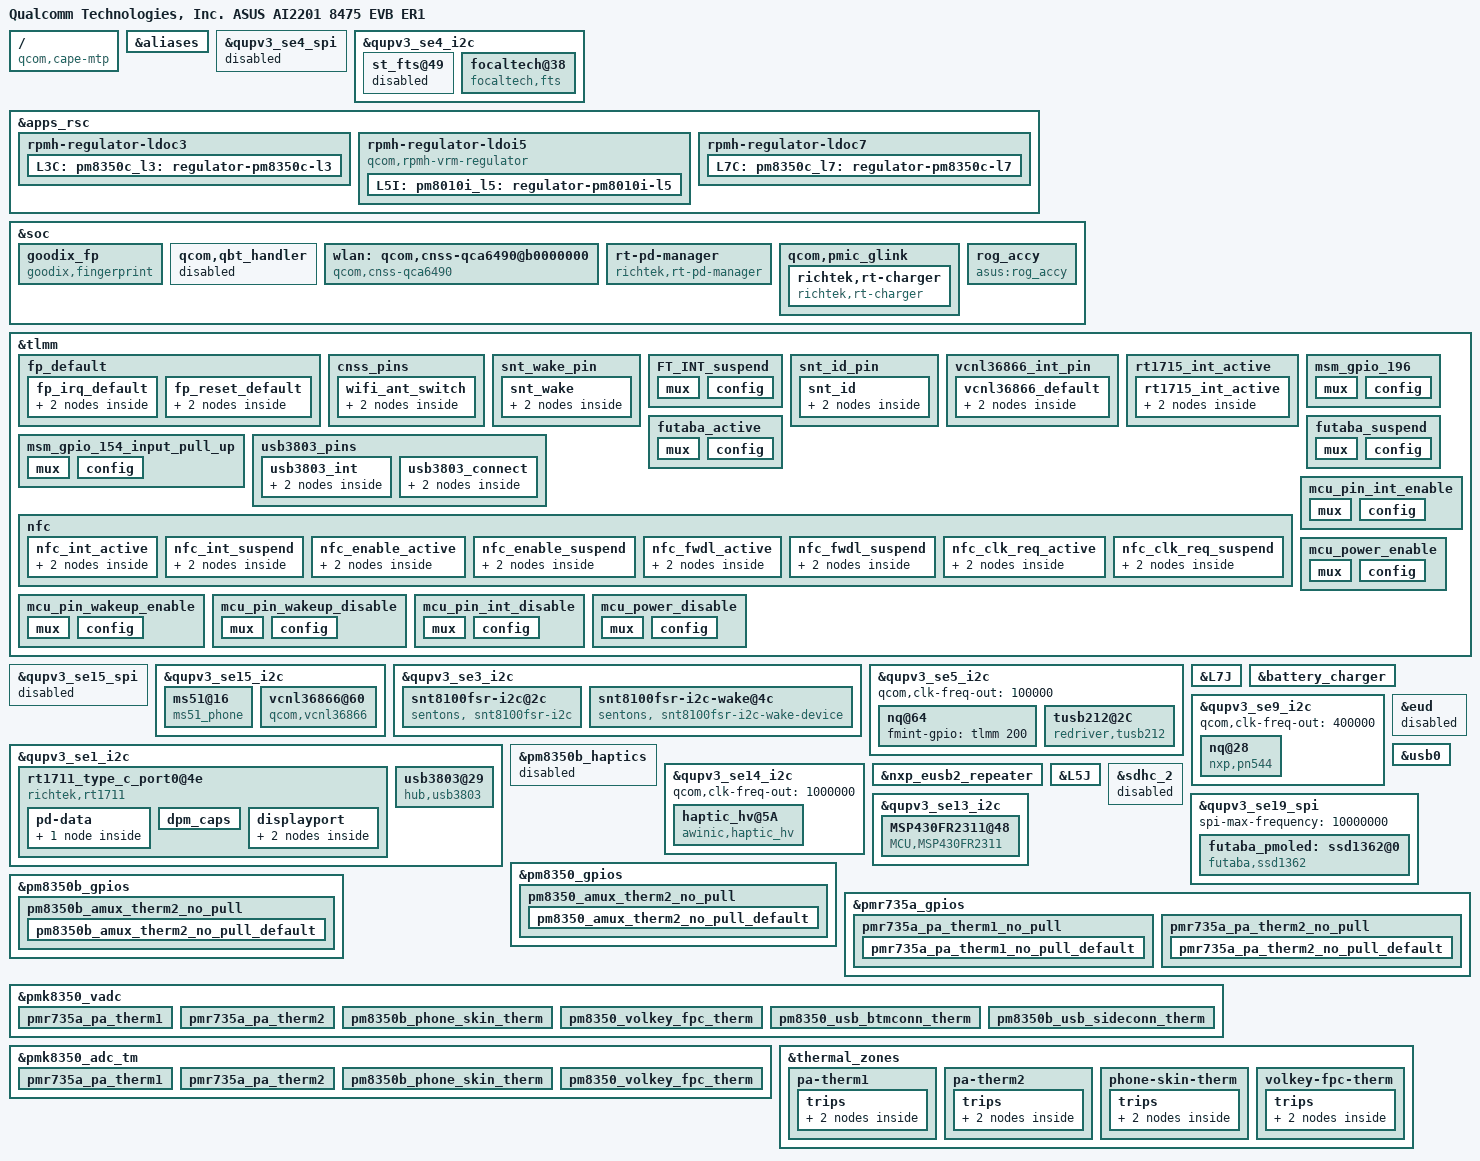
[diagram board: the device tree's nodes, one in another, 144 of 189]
/dts-v1/;
/plugin/;

#include "cape-mtp.dtsi"
#include "waipio-pm8010-spmi.dtsi"
#include <dt-bindings/clock/qcom,rpmh.h>

/ {
	model = "Qualcomm Technologies, Inc. ASUS AI2201 8475 EVB ER1";
	compatible = "qcom,cape-mtp", "qcom,cape", "qcom,mtp";
	qcom,msm-id = <530 0x10000>, <531 0x10000>, <540 0x10000>;
	qcom,board-id = <52 0>;
};
&aliases {
		i2c0 = "/soc/i2c@984000";
		i2c1 = "/soc/i2c@98c000";
		i2c2 = "/soc/i2c@990000";
		i2c3 = "/soc/i2c@994000";
		i2c4 = "/soc/i2c@a84000";
		i2c5 = "/soc/i2c@a94000";
		i2c6 = "/soc/i2c@a98000";
		i2c7 = "/soc/i2c@880000";
		i2c8 = "/soc/i2c@888000";
};

/*   ====================================
*    overlay for display - start
*    ====================================
*/

/*   ====================================
*    overlay for display - end
*    ====================================
*/

/*   ====================================
*    overlay for touch - start
*    ====================================
*/

&qupv3_se4_spi {
    status = "disable";
};

&qupv3_se4_i2c {
	status = "ok";

	st_fts@49 {
		status = "disable";
	};

	focaltech@38 {
		compatible = "focaltech,fts";
		reg = <0x38>;
		interrupt-parent = <&tlmm>;
		interrupts = <21 0x2008>;
		focaltech,reset-gpio = <&tlmm 20 0x00>;
		focaltech,irq-gpio = <&tlmm 21 0x2008>;
		focaltech,vddio = <&tlmm 105 0x00>;
		focaltech,max-touch-number = <10>;
		focaltech,display-coords = <0 0 1080 2448>;
		focaltech,touch-type = "primary";

		vdd-supply = <&L3C>;
		vcc_i2c-supply = <&L2C>;

		pinctrl-names = "pmx_ts_active", "pmx_ts_suspend","pmx_ts_release";
		pinctrl-0 = <&ts_active>;
		pinctrl-1 = <&ts_int_suspend &ts_reset_suspend>;
		pinctrl-2 = <&ts_release>;
		//panel = <&dsi_ams667uu07_fhd_plus_dsc_cmd &dsi_ams678_fhd_plus_dsc_cmd &dsi_ams678_er2_fhd_plus_dsc_cmd>
	};
};


&apps_rsc {
	rpmh-regulator-ldoc3 {
		L3C: pm8350c_l3: regulator-pm8350c-l3 {
			regulator-min-microvolt = <3008000>;
			regulator-max-microvolt = <3008000>;
			qcom,init-voltage = <3008000>;
			};
	};
};

/*   ====================================
*    overlay for touch - end
*    ====================================
*/

/*    ====================================
 *    overlay for cape.dtsi - start
 *    ====================================
 */

//ASUS_BSP Fingerprint +++
&soc {
	goodix_fp {
		compatible = "goodix,fingerprint";
		fp-gpio-irq = <&tlmm 40 0x00>;
		fp-gpio-reset = <&tlmm 71 0x0>;
		vcc-supply = <&L5I>;
		asus-fp,vcc-voltage=<3000000 3300000>;
		pinctrl-names = "fp_default";
		pinctrl-0 = <&fp_irq_default &fp_reset_default>;
		status = "okay";
	};

	//Disable qcom default FP setting
	qcom,qbt_handler {
		status = "disable";
	};
};

&tlmm{
	fp_default {
		fp_irq_default: fp_irq_default {
			mux {
				pins = "gpio40";
				function = "gpio";
			};
			config {
				pins = "gpio40";
				bias-disable;
				drive-strength = <8>;
			};
		};

		fp_reset_default: fp_reset_default {
			mux {
				pins = "gpio71";
				function = "gpio";
			};
			config {
				pins = "gpio71";
				bias-pull-down;
				drive-strength = <8>;
			};
		};
	};
};

&apps_rsc {
	rpmh-regulator-ldoi5 {
		compatible = "qcom,rpmh-vrm-regulator";
		qcom,resource-name = "ldoi5";
		qcom,regulator-type = "pmic5-ldo";
		qcom,supported-modes =
			<RPMH_REGULATOR_MODE_LPM
			 RPMH_REGULATOR_MODE_HPM>;
		qcom,mode-threshold-currents = <0 10000>;
		L5I: pm8010i_l5: regulator-pm8010i-l5 {
				regulator-name = "pm8010i_l5";
				qcom,set = <RPMH_REGULATOR_SET_ALL>;
				regulator-min-microvolt = <2800000>;
				regulator-max-microvolt = <3300000>;
				qcom,init-voltage = <3000000>;
				qcom,init-mode = <RPMH_REGULATOR_MODE_HPM>;
		};
	};
};
//ASUS_BSP Fingerprint ---

//ASUS_BSP Wifi+++
&soc {
	wlan: qcom,cnss-qca6490@b0000000 {
		compatible = "qcom,cnss-qca6490";
		pinctrl-names = "wlan_en_active", "wlan_en_sleep", "wifi_ant_gpio";
		pinctrl-0 = <&cnss_wlan_en_active>;
		pinctrl-1 = <&cnss_wlan_en_sleep>;
		pinctrl-2 = <&wifi_ant_switch>;
		wlan-asus_ant_151 = <&tlmm 151 0>;
	};
};

&tlmm {
	cnss_pins {
		wifi_ant_switch: wifi_ant_switch {
			mux {
				pins = "gpio151";
				function = "gpio";
			};

			config {
				pins = "gpio151";
				bias-pull-up;
				output-high;
			};
		};
	};
};

/*   ====================================
*    overlay for aura - start
*    ====================================
*/


&qupv3_se15_spi {
    status = "disable";
};
&qupv3_se15_i2c {
    status = "ok";
    ms51@16 {
        compatible = "ms51_phone";
        reg = <0x16>;


        nuvoton,aura_3p3_en = <0 0 0>;
        nuvoton,front_led_en = <0 0 0>;
        nuvoton,logo_5p0_en = <&pm8350c_gpios 2 0x0>;
        nuvoton,wakeup_pin = <&tlmm 109 0>;
        nuvoton,hw_stage = <5>;
    };
};

/*   ====================================
*    overlay for aura - end
*    ====================================
*/
/* ASUS BSP Clay +++: AirTrigger sensor */
&qupv3_se3_i2c {
	status = "ok";
	snt8100fsr-i2c@2c {
		reg = <0x2c>;
		compatible = "sentons, snt8100fsr-i2c";

		qcom,snt-host1-gpio = <&tlmm 44 0x0>;
		rst_gpios = <&tlmm 129 0x0>;
		snt-id-gpio = <&tlmm 174 GPIO_ACTIVE_HIGH>;
		vcc_grip_2v8-supply = <&pm8010j_l7>;
		vcc_grip_1v2-supply = <&pm8350c_l10>;
		vcc_grip_1v8-supply = <&pm8350_s10>;

		pinctrl-names = "snt_wake", "FT_INT_suspend", "snt_id";
		pinctrl-0 = <&snt_wake>;
		pinctrl-1 = <&FT_INT_suspend>;
		pinctrl-2 = <&snt_id>;
	};
	snt8100fsr-i2c-wake@4c {
		reg = <0x4c>;
		wake-device = <1>;
		compatible = "sentons, snt8100fsr-i2c-wake-device";
	};
};
// change 44 to 200 since 44 is used for AT, and 200 can't be used
&qupv3_se5_i2c {
	nq@64 {
		fmint-gpio = <&tlmm 200 0>;
	};
};

&tlmm {
	snt_wake_pin {
		snt_wake: snt_wake {
			mux {
				pins = "gpio186";
				function = "gpio";
			};
			config {
				pins = "gpio186";
				bias-pull-down;
				drive-strength = <2>;
			};
		};
	};

	FT_INT_suspend: FT_INT_suspend {
		mux {
			pins = "gpio44";
			function = "gpio";
		};

		config {
			pins = "gpio44";
			bias-disable = <0>; /* no pull */
			drive-strength = <2>;
		};
	};

	snt_id_pin {
		snt_id: snt_id {
			mux {
				pins = "gpio174";
				function = "gpio";
			};
			config {
				pins = "gpio174";
				bias-pull-down;
				drive-strength = <2>;
			};
		};
	};
};
&L7J{
	regulator-min-microvolt = <2800000>;
	regulator-max-microvolt = <2800000>;
	qcom,init-voltage = <2800000>;
};
/* ASUS BSP Clay ---: AirTrigger sensor */

// ASUS_BSP +++ Wilson vcnl36866
&qupv3_se15_i2c {
        status = "ok";
            vcnl36866@60 {
                       compatible = "qcom,vcnl36866";
                       reg = <0x60>;
                       pinctrl-names = "alsps_gpio_no_pull";
                       pinctrl-0 = <&vcnl36866_default>;
                       qcom,alsps-gpio = <&tlmm 14 0x0>;
                       vcc_psensor-supply = <&pm8350c_l7>;
                       vcc_psensor_1v8-supply  = <&pm8350c_l8>;
               };
};

&apps_rsc {
       rpmh-regulator-ldoc7 {
               L7C: pm8350c_l7: regulator-pm8350c-l7 {
                       regulator-min-microvolt = <3000000>;
                       regulator-max-microvolt = <3300000>;
                       qcom,init-voltage = <3000000>;
               };
       };
};

&tlmm {
       vcnl36866_int_pin {
               vcnl36866_default: vcnl36866_default {
                       mux {
                               pins = "gpio14";
                               function = "gpio";
                       };
                       config {
                               pins = "gpio14";
                               bias-disable = <0>; /* no pull */
                               drive-strength = <2>;
                       };
               };
       };
};
// ASUS_BSP --- Wilson vcnl36866

/*    ====================================
 *    overlay for cape.dtsi - end
 *    ====================================
 */

/*    ====================================
 *    overlay for cape-mtp.dtsi - start
 *    ====================================
 */
 //[+++] ASUS_BSP : Add for charger
&battery_charger {
	//POGO_OTG_EN = <&pm8350c_gpios 3 0x0>;

	io-channels = <&pmk8350_vadc PM8350B_ADC7_GPIO2_100K_PU>,
			 <&pmk8350_vadc PM8350_ADC7_AMUX_THM2_100K_PU>;
	io-channel-names ="pm8350b_amux_thm6", "pm8350_amux_thm2";

	//panel = <&dsi_ams667uu07_fhd_plus_dsc_cmd &dsi_ams678_fhd_plus_dsc_cmd &dsi_ams678_er2_fhd_plus_dsc_cmd>;
};
//[---] ASUS_BSP : Add for charger

//ASUS BSP Richtek TypeC PD +++
&qupv3_se1_i2c {
	status = "ok";
		rt1711_type_c_port0@4e {
		compatible = "richtek,rt1711";
		reg = <0x4e>;
		rt1711,irq_pin = <&tlmm 19 0x00>;
		rt-dual,supported_modes = <0>; /* 0: dfp/ufp, 1: dfp, 2: ufp */
		rt-tcpc,name = "typec"; /* tcpc_device's name */
		rt-tcpc,role_def = <4>; /* 0: SNK Only, 1: SRC Only, 2: DRP, 3: Try.SRC, 4: Try.SNK */
		rt-tcpc,rp_level = <0>; /* 0: Default, 1: 1.5, 2: 3.0 */
		rt-tcpc,vconn_supply  = <0>;  /* 0: Never, 1: Always, 2: EMarkOnly, 3: StartOnly */
		rt-tcpc,notifier_supply_num = <1>; /* the number of notifier supply */
		pinctrl-names = "rt1715_int_active";
		pinctrl-0 = <&rt1715_int_active>;
		pd-data {
			pd,vid = <0x29cf>;
			pd,pid = <0x1711>;
			pd,source-cap-ext = <0x171129cf 0x00000000 0x00000102 0x00000000 0x00000000 0x02000000 0x00>;
			pd,mfrs = "RichtekTCPC";

			/*
			 *	VSAFE5V = 0, MAX_POWER = 1, CUSTOM = 2,
			 *	MAX_POWER_LV = 0x21, MAX_POWER_LVIC = 0x31
			 *	MAX_POWER_HV = 0x41, MAX_POWER_HVIC = 0x51
			 */
				pd,charging_policy= <0x21>;

			/*
			 * Fixed 5V, 500 mA <0x00019032>
			 * Fixed 5V, 1A <0x00019064>
			 * Fixed 5V, 2A <0x000190c8>
			 * Fixed 5V, 3A <0x0001912c>
			 * Fixed 9V, 500 mA <0x0002d032>
			 * Fixed 9V, 1A <0x0002d064>
			 * Fixed 9V, 2A <0x0002d0c8>
			 * Fixed 9V, 3A <0x0002d12c>
			 * Variable 5-9V, 1A <0x8642d064>
			 * Variable 5-9V, 2A <0x8642d0c8>
			 * Variable 5-9V, 3A <0x8642d12c>
			 * PPS 3V~5.9V, 3A <0xC0761E3C>
			 */
				pd,source-pdo-size = <1>;
				pd,source-pdo-data = <0x00019032>; /* 5V, 500 mA */
				pd,sink-pdo-size = <1>;
				pd,sink-pdo-data = <0x000190c8> ;   /* 0x0002d0c8 : 9V, 2A<0x04019032 0x04019064> */

			/*
			 * No DP, host + device
			 *	pd,id-vdo-size = <3>;
					pd,id-vdo-data = <0xd00029cf 0x0 0x00010000>;
			 * With DP
			 *	pd,id-vdo-size = <4>;
					pd,id-vdo-data = <0xec0029cf 0x0 0x00010000 0x11000001>;
			 */

				pd,id-vdo-size = <6>;
				pd,id-vdo-data = <0xd14029cf 0x0 0x17110000
							0x61000000 0x0 0x41000000>;

			bat,nr = <1>;
			pd,country_nr = <0>;

			bat-info0 {
				bat,vid = <0x29cf>;
				bat,pid = <0x1711>;
				bat,mfrs = "bat1";
				bat,design_cap = <3000>;
			};

			//bat-info1 {
			//	bat,vid = <0x8abc>;
			//	bat,pid = <0x5234>;
			//	bat,mfrs = "bat2";
			//	bat,design_cap = <4000>;
			//};

			//country0 {
			//	pd,country_code = <0x5457>;
			//	pd,country_len = <2>; /* max len = 26 */
			//	pd,country_data = <0xff 0xff>;
			//};

			//country1 {
			//	pd,country_code = <0x5553>;
			//	pd,country_len = <3>; /* max len = 26 */
			//	pd,country_data = <0xf1 0xf2 0xf3>;
			//};
		};

		dpm_caps {
			local_dr_power;
			local_dr_data;
			//local_ext_power;
			local_usb_comm;
			//local_usb_suspend;
			//local_high_cap;
			//local_give_back;
			local_no_suspend;
			//local_vconn_supply;

			//attemp_discover_cable_dfp;
			//attemp_enter_dp_mode;
			//attemp_discover_cable;
			attemp_discover_id;
			/* 0: disable, 1: prefer_snk, 2: prefer_src */
			pr_check = <0>;
			//pr_reject_as_source;
			//pr_reject_as_sink;
			pr_check_gp_source;
			//pr_check_gp_sink;

			/* 0: disable, 1: prefer_ufp, 2: prefer_dfp */
			dr_check = <0>;
			//dr_reject_as_dfp;
			//dr_reject_as_ufp;
		};
		displayport {
			/* connection type = "both", "ufp_d", "dfp_d" */
			1st_connection = "dfp_d";
			2nd_connection = "dfp_d";
			signal,dp_v13;
			//signal,dp_gen2;
			usbr20_not_used;
			typec,receptacle;
			ufp_d {
				//pin_assignment,mode_a;
				//pin_assignment,mode_b;
				//pin_assignment,mode_c;
				//pin_assignment,mode_d;
				//pin_assignment,mode_e;
			};
			dfp_d {
				/* Only support mode C & D */
				//pin_assignment,mode_a;
				//pin_assignment,mode_b;
				pin_assignment,mode_c;
				pin_assignment,mode_d;
				pin_assignment,mode_e;
				pin_assignment,mode_f;
			};
		};
	};
};

&soc {

	rt-pd-manager {
		compatible = "richtek,rt-pd-manager";
	};

	qcom,pmic_glink {
		richtek,rt-charger {
			compatible = "richtek,rt-charger";
			//vconn-supply = <&vconn_5v>;
		};
	};

};
//ASUS BSP Richtek TypeC PD ---

&tlmm {
	//ASUS BSP Richtek TypeC PD +++
	rt1715_int_active {
		rt1715_int_active: rt1715_int_active {
			mux {
				pins = "gpio19";
				function = "gpio";
			};

			config {
				pins = "gpio19";
				drive-strength = <2>;
				bias-pull-up;
			};
		};
	};
	//ASUS BSP Richtek TypeC PD ---
};

&qupv3_se9_i2c{
	status = "ok";
	qcom,clk-freq-out = <400000>;

	// ASUS_BSP Weihong NFC +++
	nq@28 {
		compatible = "nxp,pn544";
		reg = <0x29>;
		nxp,pn544-irq = <&tlmm 46 0x00>;
		nxp,pn544-ven = <&tlmm 34 0x00>;
		nxp,pn544-fw-dwnld = <&tlmm 45 0x00>;
		nxp,pn544-ese-pwr =  <&tlmm 187 0x00>;
		qcom,sn-clkreq = <&tlmm 35 0x00>;
		qcom,sn-vdd-1p8-supply = <&S10B>;
		qcom,sn-vdd-1p8-voltage = <1800000 1800000>;
		qcom,sn-vdd-1p8-current = <157000>;
		interrupt-parent = <&tlmm>;
		interrupts = <46 0>;
		interrupt-names = "nfc_irq";
		pinctrl-names = "nfc_active", "nfc_suspend";
		pinctrl-0 = <&nfc_int_active &nfc_enable_active
				&nfc_clk_req_active &nfc_fwdl_active>;
		pinctrl-1 = <&nfc_int_suspend &nfc_enable_suspend
				&nfc_clk_req_suspend &nfc_fwdl_suspend>;
	};
	// ASUS_BSP Weihong NFC ---
};

&eud {
	status = "disabled";
};

//ASUS_BSP: disable qcom haptic
&pm8350b_haptics {
    status = "disabled";
};
//ASUS_BSP: aw haptic +++
&qupv3_se14_i2c {
	status = "ok";
	qcom,clk-freq-out = <1000000>;
	#address-cells = <1>;
	#size-cells = <0>;

	haptic_hv@5A {
		compatible = "awinic,haptic_hv";
		reg = <0x5A>;
		irq-gpio = <&tlmm 154 0>;
		reset-gpio = <&tlmm 108 0>;
		pinctrl-names = "irq_active";
		pinctrl-0 = <&msm_gpio_154_input_pull_up &msm_gpio_196>;
		f0_pre = < 1300 >;
		mode = /bits/ 8 < 5 >;
		f0_cali_percent = /bits/ 8 < 15 >;

/*******************************aw869x*******************************/
		aw869x_max_bst_vol = /bits/ 8 <0x1f>;
		aw869x_cont_drv_lev = /bits/ 8 < 105 >;
		aw869x_cont_drv_lvl_ov = /bits/ 8 < 125 >;
		aw869x_cont_td = < 0x009A >;
		aw869x_cont_zc_thr = < 0x0FF1 >;
		aw869x_cont_num_brk = /bits/ 8 < 3 >;
		aw869x_f0_coeff = < 260 >; /*Don't modify it 2.604167*/
		aw869x_duration_time = /bits/ 8 < 20 30 60 >;
		aw869x_f0_trace_parameter = /bits/ 8 < 0x05 0x03 0x02 0x0f >;
		aw869x_bemf_config = /bits/ 8 < 0x10 0x08 0x03 0xf8 >;
		aw869x_tset = /bits/ 8 < 0x12 >;
		aw869x_r_spare = /bits/ 8 < 0x68 >;
		aw869x_bstdbg = /bits/ 8 < 0x30 0xeb 0xd4 0 0 0 >;
		aw869x_trig_config = /bits/ 8 < 0 1 1 1 2 0 1 1 1 2 0 1 1 1 2 >;
		aw869x_bst_vol_default = < 8500 >;

/******************************aw869xx*******************************/
		aw869xx_gain_bypass = /bits/ 8 < 1 >;
		aw869xx_max_bst_vol = /bits/ 8 <0x3f>;
		aw869xx_brk_bst_md = /bits/ 8 < 0 >;
		aw869xx_cont_drv1_lvl = /bits/ 8 < 0x7F >;
		aw869xx_cont_drv2_lvl = /bits/ 8 < 0x36 >;
		aw869xx_cont_brk_time = /bits/ 8 < 0x08 >;
		aw869xx_cont_tset = /bits/ 8 < 0x06 >;
		aw869xx_cont_bemf_set = /bits/ 8 < 0x02 >;
		aw869xx_cont_drv_width = /bits/ 8 < 0x6A >;
		aw869xx_cont_track_margin = /bits/ 8 < 0x12 >;
		aw869xx_cont_brk_gain = /bits/ 8 < 0x08 >;
		aw869xx_cont_bst_brk_gain = /bits/ 8 < 0x05 >;
		aw869xx_cont_wait_num = /bits/ 8 < 0x06 >;
		aw869xx_cont_drv1_time = /bits/ 8 < 0x04 >;
		aw869xx_cont_drv2_time = /bits/ 8 < 0x14 >;
		aw869xx_duration_time = /bits/ 8 < 20 30 60 >;
		aw869xx_sine_array = /bits/ 8 < 0x05 0xB2 0xFF 0xEF >;
		aw869xx_d2s_gain = /bits/ 8 < 0x04 >;
		aw869xx_bstcfg = /bits/ 8 < 0x20 0x24 0x96 0x40 0x11 >;
		aw869xx_trig_config = /bits/ 8 < 0 0 0 1 0 2 0 0
						 0 0 0 1 0 2 0 0
						 0 0 0 1 0 2 0 0 >;
		aw869xx_bst_vol_default = < 8500 >;
		/* aw869xx_is_enabled_auto_bst; */
		/* aw869xx_is_enabled_i2s; */
		/* aw869xx_is_enabled_one_wire; */

/******************************aw8671x*******************************/
		aw8671x_gain_bypass = /bits/ 8 < 1 >;
		aw8671x_brk_bst_md = /bits/ 8 < 0 >;
		aw8671x_cont_drv1_lvl = /bits/ 8 < 0x7F >;
		aw8671x_cont_drv2_lvl = /bits/ 8 < 0x36 >;
		aw8671x_cont_brk_time = /bits/ 8 < 0x08 >;
		aw8671x_cont_tset = /bits/ 8 < 0x06 >;
		aw8671x_cont_bemf_set = /bits/ 8 < 0x02 >;
		aw8671x_cont_drv_width = /bits/ 8 < 0x6A >;
		aw8671x_cont_track_margin = /bits/ 8 < 0x12 >;
		aw8671x_cont_brk_gain = /bits/ 8 < 0x08 >;
		aw8671x_cont_bst_brk_gain = /bits/ 8 < 0x05 >;
		aw8671x_cont_wait_num = /bits/ 8 < 0x06 >;
		aw8671x_cont_drv1_time = /bits/ 8 < 0x04 >;
		aw8671x_cont_drv2_time = /bits/ 8 < 0x14 >;
		aw8671x_duration_time = /bits/ 8 < 20 30 60 >;
		aw8671x_d2s_gain = /bits/ 8 < 0x04 >;
		aw8671x_trig_config = /bits/ 8 < 0 0 0 1 0 2 0 0
						 0 0 0 1 0 2 0 0
						 0 0 0 1 0 2 0 0 >;
		aw8671x_bst_vol_default = < 6336 >;
		/* aw8671x_is_enabled_auto_bst; */
		/* aw8671x_is_enabled_i2s; */
		/* aw8671x_is_enabled_one_wire; */

/******************************aw8692x*******************************/
		aw8692x_gain_bypass = /bits/ 8 < 1 >;
		aw8692x_cont_drv1_lvl = /bits/ 8 < 0x7F >;
		aw8692x_cont_drv2_lvl = /bits/ 8 < 0x50 >;
		aw8692x_cont_drv1_time = /bits/ 8 < 0x04 >;
		aw8692x_cont_drv2_time = /bits/ 8 < 0x06 >;
		aw8692x_cont_drv_width = /bits/ 8 < 0x9C >;
		aw8692x_cont_track_margin = /bits/ 8 < 0x0C >;
		aw8692x_cont_brk_gain = /bits/ 8 < 0x08 >;
		aw8692x_cont_bst_brk_gain = /bits/ 8 < 0x05 >;
		aw8692x_cont_wait_num = /bits/ 8 < 0x06 >;
		aw8692x_cont_brk_time = /bits/ 8 < 0x08 >;
		aw8692x_brk_bst_md = /bits/ 8 < 0 >;
		aw8692x_cont_tset = /bits/ 8 < 0x06 >;
		aw8692x_cont_bemf_set = /bits/ 8 < 0x02 >;
		aw8692x_duration_time = /bits/ 8 < 20 30 60 >;
		aw8692x_d2s_gain = /bits/ 8 < 0x04 >;
		aw8692x_trig_config = /bits/ 8 < 0 0 1 3 0 2 0 0
						 0 0 1 4 0 2 0 0
						 0 0 0 1 0 2 0 0 >;
		aw8692x_bst_vol_default = < 8000 >;
		/* aw8692x_is_enabled_auto_bst; */
		/* aw8692x_is_enabled_one_wire; */
	};
};

&tlmm {

	/* GPIO_154 : INTERRUPT_N */
	msm_gpio_154_input_pull_up: msm_gpio_154_input_pull_up {
		mux {
			 pins = "gpio154";
			 function = "gpio";
		};

		config {
			pins = "gpio154";
			drive-strength = <2>;
			bias-pull-up;
			input-enable;
		};
	};

	/* GPIO_196 : trig */
	msm_gpio_196: msm_gpio_196 {
		mux {
			 pins = "gpio196";
			 function = "gpio";
		};

		config {
			pins = "gpio196";
			drive-strength = <2>;
			bias-pull-down;
			output-low;
		};
	};

};
//ASUS_BSP: aw haptic ---

&nxp_eusb2_repeater {
	qcom,param-override-seq =
		/bits/ 8 <0x60 0x06
			  0x02 0x07
			  0x62 0x08>;
};

//ASUS_BSP: usb mux +++
&usb0 {
	MUX1_OE = <&tlmm 172 0x0>;
	MUX2_OE = <&tlmm 171 0x0>;
	MUX2_SEL = <&tlmm 122 0x0>;
};
//ASUS_BSP: usb mux ---

//ASUS_BSP: usb hub +++
&qupv3_se1_i2c {
	status = "ok";
	usb3803@29 {
		compatible = "hub,usb3803";
		reg = <0x29>;

		clock-names = "bb_clk3";
		clocks = <&clock_rpmh RPMH_LN_BB_CLK3>;

		HUB_BYPASS = <&tlmm 124 0x0>;
		HUB_RESET = <&tlmm 125 0x0>;
		HUB_CONNECT = <&tlmm 121 0x0>;

		pinctrl-names = "hub_int", "hub_connect";
		pinctrl-0 = <&usb3803_int>;
		pinctrl-1 = <&usb3803_connect>;
	};
};

&tlmm{
	usb3803_pins {
		usb3803_int: usb3803_int {
			mux {
				pins = "gpio119";
				function = "gpio";
			};
			config {
				pins = "gpio119";
				bias-disable;
				drive-strength = <2>;
			};
		};

		usb3803_connect: usb3803_connect {
			mux {
				pins = "gpio121";
				function = "gpio";
			};
			config {
				pins = "gpio121";
				bias-pull-up;
				output-high;
			};
		};
	};
};
//ASUS_BSP: usb hub ---

//ASUS_BSP: usb redriver +++
&qupv3_se5_i2c {
	status = "ok";
	qcom,clk-freq-out = <100000>;

	tusb212@2C {
		compatible = "redriver,tusb212";
		reg = <0x2C>;

		REDRIVER_RESET = <&tlmm 7 0x0>;
		REDRIVER_CD = <&tlmm 209 0x0>;

		vcc_redriver-supply = <&pm8010j_l5>;
	};
};
&L5J{
	regulator-min-microvolt = <2800000>;
	regulator-max-microvolt = <3304000>;
	qcom,init-voltage = <3304000>;
};
//ASUS_BSP: usb redriver ---


//ASUS BSP Deeo : ROG ACCY driver +++
&soc {
	rog_accy {
		compatible = "asus:rog_accy";
		status = "okay";
	};
};
//ASUS BSP Deeo : ROG ACCY driver ---

//MCU use gpio92 for interrupt pin
&sdhc_2 {
	status = "disable";
};

/*    ====================================
 *    overlay for cape-mtp.dtsi - end
 *    ====================================
 */

/*    ====================================
 *    overlay for cape-pinctrl.dtsi - start
 *    ====================================
 */

/* for PMOLED */
/* futaba pmoled pins */
&tlmm {
	futaba_active: futaba_active {
		mux {
			pins = "gpio66", "gpio93", "gpio107", "gpio70";
			function = "gpio";
		};
		config {
			pins = "gpio66", "gpio93", "gpio107", "gpio70";
			drive-strength = <8>;
			bias-pull-up;
		};
	};

	futaba_suspend: futaba_suspend {
		mux {
			pins = "gpio66", "gpio93", "gpio107", "gpio70";
			function = "gpio";
		};
		config {
			pins = "gpio66", "gpio93", "gpio107", "gpio70";
			drive-strength = <2>;
			bias-disabled;
		};
	};
};

&tlmm{
	nfc {
		nfc_int_active: nfc_int_active {
			/* active state */
			mux {
				/* NFC Read Interrupt */
				pins = "gpio46";
				function = "gpio";
			};

			config {
				pins = "gpio46";
				drive-strength = <2>; /* 2 MA */
				bias-pull-down;
			};
		};

		nfc_int_suspend: nfc_int_suspend {
			/* sleep state */
			mux {
				/* NFC Read Interrupt */
				pins = "gpio46";
				function = "gpio";
			};

			config {
				pins = "gpio46";
				drive-strength = <2>; /* 2 MA */
				bias-pull-down;
			};
		};

		nfc_enable_active: nfc_enable_active {
			mux {
				/* Enable, Firmware and Clock request gpios */
				pins = "gpio34";
				function = "gpio";
			};

			config {
				pins = "gpio34";
				drive-strength = <2>; /* 2 MA */
				bias-disable;
			};
		};

		nfc_enable_suspend: nfc_enable_suspend {
			mux {
				pins = "gpio34";
				function = "gpio";
			};

			config {
				pins = "gpio34";
				drive-strength = <2>; /* 2 MA */
				bias-disable;
			};
		};

		nfc_fwdl_active: nfc_fwdl_active {
			mux {
				/* 45: Firmware */
				pins = "gpio45";
				function = "gpio";
			};

			config {
				pins = "gpio45";
				drive-strength = <2>; /* 2 MA */
				bias-disable;
			};
		};

		nfc_fwdl_suspend: nfc_fwdl_suspend {
			mux {
				/*45: Firmware */
				pins = "gpio45";
				function = "gpio";
			};

			config {
				pins = "gpio45";
				drive-strength = <2>; /* 2 MA */
				bias-disable;
			};
		};

		nfc_clk_req_active: nfc_clk_req_active {
			/* active state */
			mux {
				/* GPIO 35: NFC CLOCK REQUEST */
				pins = "gpio35";
				function = "gpio";
			};

			config {
				pins = "gpio35";
				drive-strength = <2>; /* 2 MA */
				bias-pull-up;
			};
		};

		nfc_clk_req_suspend: nfc_clk_req_suspend {
			/* sleep state */
			mux {
				/* GPIO 35: NFC CLOCK REQUEST */
				pins = "gpio35";
				function = "gpio";
			};

			config {
				pins = "gpio35";
				drive-strength = <2>; /* 2 MA */
				bias-disable;
			};
		};
	};
};

// MCU porting
&tlmm{
	mcu_pin_wakeup_enable: mcu_pin_wakeup_enable {
		mux {
			pins = "gpio118";
			function = "gpio";
		};
		config {
			pins = "gpio118";
			bias-pull-down;
			drive-strength = <2>; /* 2 MA */
			input-enable;
		};
	};

	mcu_pin_wakeup_disable: mcu_pin_wakeup_disable {
		mux {
			pins = "gpio118";
			function = "gpio";
		};
		config {
			pins = "gpio118";
			bias-pull-down;
			drive-strength = <2>; /* 2 MA */
			input-enable;
		};
	};

	mcu_pin_int_enable: mcu_pin_int_enable {
		mux {
			pins = "gpio92";
			function = "gpio";
		};
		config {
			pins = "gpio92";
			bias-disable = <0>; /* no pull */
			drive-strength = <2>; /* 2 MA */
			input-enable;
		};
	};

	mcu_pin_int_disable: mcu_pin_int_disable {
		mux {
			pins = "gpio92";
			function = "gpio";
		};
		config {
			pins = "gpio92";
			bias-disable = <0>; /* no pull */
			drive-strength = <2>; /* 2 MA */
			input-enable;
		};
	};

	mcu_power_enable: mcu_power_enable {
		mux {
			pins = "gpio178";
			function = "gpio";
		};
		config {
			pins = "gpio178";
			bias-pull-up;
			drive-strength = <2>; /* 2 MA */
		};
	};

	mcu_power_disable: mcu_power_disable {
		mux {
			pins = "gpio178";
			function = "gpio";
		};
		config {
			pins = "gpio178";
			bias-pull-down;
			drive-strength = <2>; /* 2 MA */
		};
	};
};

/*    ====================================
 *    overlay for cape-pinctrl.dtsi - end
 *    ====================================
 */

/*    ====================================
 *    overlay for cape waipio-qupv3.dtsi - start
 *    ====================================
 */

&qupv3_se13_i2c {
	status = "ok";
	MSP430FR2311@48 {
		compatible = "MCU,MSP430FR2311";
		reg = <0x48>;
		//vcc_s4a_1p8-supply = <&pm8150_s4>;
		//vcc_l10a_3p3-supply = <&pm8350c_l11>;
		pinctrl-names = "mcu_active", "mcu_suspend";
		pinctrl-0 = <&mcu_pin_wakeup_enable &mcu_pin_int_enable &mcu_power_enable>;
		pinctrl-1 = <&mcu_pin_wakeup_disable &mcu_pin_int_disable &mcu_power_disable>;
		gpios = <&tlmm 118 0>, <&tlmm 92 0>, <&tlmm 178 0>;

		MCU,mcureset-gpios = <&pm8350c_gpios 5 0x0>;
		MCU,mcutest-gpios = <&pm8350b_gpios 5 0x0>;
		MCU,mcuwakeup-gpios = <&tlmm 118 0x00>;
		MCU,mcuint-gpios = <&tlmm 92 0x00>;
		MCU,power-gpios = <&tlmm 178 0x00>;
		MCU,slave_address = <0x48>;
	};
};

/* for PMOLED */
&qupv3_se19_spi {
	status = "ok";
	spi-max-frequency = <10000000>;

	futaba_pmoled: ssd1362@0 {
		compatible = "futaba,ssd1362";
		reg = <0>;
		spi-max-frequency = <10000000>;
		futaba,reset-gpio = <&tlmm 70 0>;
		futaba,dc-gpio = <&tlmm 107 0>;
		futaba,pwren-gpio = <&tlmm 93 0>;
		futaba,vci-gpio = <&tlmm 66 0>;
		// to determine if there is PMOLED on the board
		asus,light-guide-film-id1 = <&tlmm 188 0>;
		asus,light-guide-film-id2 = <&tlmm 189 0>;
		asus,light-guide-film-con-id = <&tlmm 105 0>;
		asus,hardware-stage = "er";

		pinctrl-names = "futaba_active", "futaba_suspend";
		pinctrl-0 = <&futaba_active>;
		pinctrl-1 = <&futaba_suspend>;
	};
};

/*    ====================================
 *    overlay for cape waipio-qupv3.dtsi - end
 *    ====================================
 */

 /*    ====================================
 *    overlay for cape-pmic-overlay.dtsi - start
 *    ====================================
 */

&pm8350_gpios {
	/delete-node/ pm8350_rear_tof_therm;
};

&pmr735a_gpios {
	pmr735a_pa_therm1_no_pull {
		pmr735a_pa_therm1_no_pull_default: pmr735a_pa_therm1_no_pull_default {
			pins = "gpio1";
			bias-disable;
		};
	};

	pmr735a_pa_therm2_no_pull {
		pmr735a_pa_therm2_no_pull_default: pmr735a_pa_therm2_no_pull_default {
			pins = "gpio2";
			bias-disable;
		};
	};
};

&pm8350b_gpios {
	pm8350b_amux_therm2_no_pull {
		pm8350b_amux_therm2_no_pull_default: pm8350b_amux_therm2_no_pull_default {
			pins = "gpio2";
			input-enable;
			bias-disable;
		};
	};
};

&pm8350_gpios {
	pm8350_amux_therm2_no_pull {
		pm8350_amux_therm2_no_pull_default: pm8350_amux_therm2_no_pull_default {
			pins = "gpio2";
			bias-disable;
		};
	};
};

&pmk8350_vadc {
	pinctrl-names = "default";
	pinctrl-0 = <&pmr735a_pa_therm1_no_pull_default &pmr735a_pa_therm2_no_pull_default &pm8350b_amux_therm2_no_pull_default &pm8350_amux_therm2_no_pull_default>;

	/delete-node/ pm8350_rear_tof_therm;

	pmr735a_pa_therm1 {
		reg = <PMR735A_ADC7_GPIO1_100K_PU>;
		label = "pmr735a_pa_therm1";
		qcom,ratiometric;
		qcom,hw-settle-time = <200>;
		qcom,pre-scaling = <1 1>;
	};
	pmr735a_pa_therm2 {
		reg = <PMR735A_ADC7_GPIO2_100K_PU>;
		label = "pmr735a_pa_therm2";
		qcom,ratiometric;
		qcom,hw-settle-time = <200>;
		qcom,pre-scaling = <1 1>;
	};
	pm8350b_phone_skin_therm {
		reg = <PM8350B_ADC7_GPIO1_100K_PU>;
		label = "pm8350b_phone_skin_therm";
		qcom,ratiometric;
		qcom,hw-settle-time = <200>;
		qcom,pre-scaling = <1 1>;
	};
	pm8350_volkey_fpc_therm {
		reg = <PM8350_ADC7_GPIO2_100K_PU>;
		label = "pm8350_volkey_fpc_therm";
		qcom,ratiometric;
		qcom,hw-settle-time = <200>;
		qcom,pre-scaling = <1 1>;
	};
	pm8350_usb_btmconn_therm {
		reg = <PM8350_ADC7_AMUX_THM2_100K_PU>;
		label = "pm8350_usb_btmconn_therm";
		qcom,ratiometric;
		qcom,hw-settle-time = <200>;
		qcom,pre-scaling = <1 1>;
	};
	pm8350b_usb_sideconn_therm {
		reg = <PM8350B_ADC7_GPIO2_100K_PU>;
		label = "pm8350b_usb_sideconn_therm";
		qcom,ratiometric;
		qcom,hw-settle-time = <200>;
		qcom,pre-scaling = <1 1>;
	};
};

&pmk8350_adc_tm {
	io-channels = <&pmk8350_vadc PM8350_ADC7_AMUX_THM1_100K_PU>,
			<&pmk8350_vadc PM8350_ADC7_AMUX_THM3_100K_PU>,
			<&pmk8350_vadc PM8350B_ADC7_AMUX_THM4_100K_PU>,
			<&pmk8350_vadc PMK8350_ADC7_AMUX_THM1_100K_PU>,
			<&pmk8350_vadc PMR735A_ADC7_GPIO1_100K_PU>,
			<&pmk8350_vadc PMR735A_ADC7_GPIO2_100K_PU>,
			<&pmk8350_vadc PM8350B_ADC7_GPIO1_100K_PU>,
			<&pmk8350_vadc PM8350_ADC7_GPIO2_100K_PU>;

	/delete-node/ pm8350_rear_tof_therm;
	/delete-node/ pm8350b_wl_chg_therm;
	/delete-node/ pm8350_cam_flash_therm;
	/delete-node/ pm8350_wide_rfc_therm;

	pmr735a_pa_therm1 {
		reg = <PMR735A_ADC7_GPIO1_100K_PU>;
		qcom,ratiometric;
		qcom,hw-settle-time = <200>;
	};

	pmr735a_pa_therm2 {
		reg = <PMR735A_ADC7_GPIO2_100K_PU>;
		qcom,ratiometric;
		qcom,hw-settle-time = <200>;
	};

	pm8350b_phone_skin_therm {
		reg = <PM8350B_ADC7_GPIO1_100K_PU>;
		qcom,ratiometric;
		qcom,hw-settle-time = <200>;
	};

	pm8350_volkey_fpc_therm {
		reg = <PM8350_ADC7_GPIO2_100K_PU>;
		qcom,ratiometric;
		qcom,hw-settle-time = <200>;
	};
};

&thermal_zones {
	/delete-node/ rear-cam-therm;
	/delete-node/ tof-therm;
	/delete-node/ wlc-therm;
	/delete-node/ camera-therm;

	pa-therm1 {
		polling-delay-passive = <0>;
		polling-delay = <0>;
		thermal-sensors = <&pmk8350_adc_tm PMR735A_ADC7_GPIO1_100K_PU>;
		trips {
			active-config0 {
				temperature = <125000>;
				hysteresis = <1000>;
				type = "passive";
			};
			active-config1 {
				temperature = <125000>;
				hysteresis = <1000>;
				type = "passive";
			};
		};
	};

	pa-therm2 {
		polling-delay-passive = <0>;
		polling-delay = <0>;
		thermal-sensors = <&pmk8350_adc_tm PMR735A_ADC7_GPIO2_100K_PU>;
		trips {
			active-config0 {
				temperature = <125000>;
				hysteresis = <1000>;
				type = "passive";
			};
			active-config1 {
				temperature = <125000>;
				hysteresis = <1000>;
				type = "passive";
			};
		};
	};

	phone-skin-therm {
		polling-delay-passive = <0>;
		polling-delay = <0>;
		thermal-sensors = <&pmk8350_adc_tm PM8350B_ADC7_GPIO1_100K_PU>;
		trips {
			active-config0 {
				temperature = <125000>;
				hysteresis = <1000>;
				type = "passive";
			};
			active-config1 {
				temperature = <125000>;
				hysteresis = <1000>;
				type = "passive";
			};
		};
	};

	volkey-fpc-therm {
		polling-delay-passive = <0>;
		polling-delay = <0>;
		thermal-sensors = <&pmk8350_adc_tm PM8350_ADC7_GPIO2_100K_PU>;
		trips {
			active-config0 {
				temperature = <125000>;
				hysteresis = <1000>;
				type = "passive";
			};
			active-config1 {
				temperature = <125000>;
				hysteresis = <1000>;
				type = "passive";
			};
		};
	};
};

 /*    ====================================
 *    overlay for cape-pmic-overlay.dtsi - end
 *    ====================================
 */

 /*    ====================================
 *    overlay for cape-regulators.dtsi - start
 *    ====================================
 */

/*    ====================================
 *    overlay for cape-regulators.dtsi - end
 *    ====================================
 */
